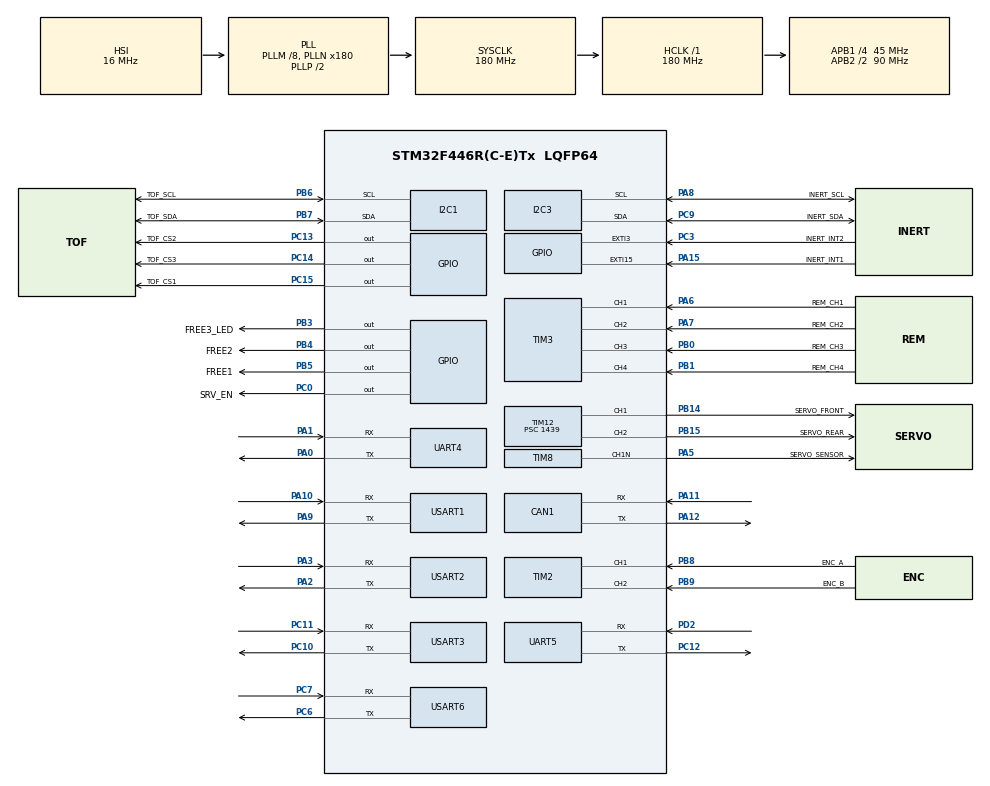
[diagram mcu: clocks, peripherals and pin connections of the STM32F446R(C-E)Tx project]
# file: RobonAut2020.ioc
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CAN1.CalculateTimeQuantum=355.55555555555554
FREERTOS.Tasks01=defaultTask,24,128,StartDefaultTask,Default,NULL,Dynamic,NULL,NULL
I2C1.I2C_Mode=I2C_Fast
Mcu.Family=STM32F4
Mcu.Name=STM32F446R(C-E)Tx
Mcu.Package=LQFP64
NVIC.I2C1_ER_IRQn=true\:5\:0\:false\:false\:true\:true\:true\:true
NVIC.I2C1_EV_IRQn=true\:5\:0\:false\:false\:true\:true\:true\:true
NVIC.I2C3_ER_IRQn=true\:5\:0\:false\:false\:true\:true\:true\:true
NVIC.I2C3_EV_IRQn=true\:5\:0\:false\:false\:true\:true\:true\:true
NVIC.PriorityGroup=NVIC_PRIORITYGROUP_4
NVIC.TIM2_IRQn=true\:5\:0\:false\:false\:true\:true\:true\:true
NVIC.TIM3_IRQn=true\:5\:0\:false\:false\:true\:true\:true\:true
NVIC.TIM7_IRQn=true\:0\:0\:false\:false\:true\:false\:false\:true
NVIC.TIM8_BRK_TIM12_IRQn=true\:5\:0\:false\:false\:true\:true\:true\:true
NVIC.TIM8_CC_IRQn=true\:5\:0\:false\:false\:true\:true\:true\:true
NVIC.TimeBase=TIM7_IRQn
NVIC.TimeBaseIP=TIM7
PA0-WKUP.Mode=Asynchronous
PA0-WKUP.Signal=UART4_TX
PA1.Mode=Asynchronous
PA1.Signal=UART4_RX
PA10.Mode=Asynchronous
PA10.Signal=USART1_RX
PA11.Mode=Master
PA11.Signal=CAN1_RX
PA12.Mode=Master
PA12.Signal=CAN1_TX
PA13.Mode=Serial_Wire
PA13.Signal=SYS_JTMS-SWDIO
PA14.Mode=Serial_Wire
PA14.Signal=SYS_JTCK-SWCLK
PA15.GPIO_Label=INERT_INT1
PA15.Signal=GPXTI15
PA2.Mode=Asynchronous
PA2.Signal=USART2_TX
PA3.Mode=Asynchronous
PA3.Signal=USART2_RX
PA5.GPIO_Label=SERVO_SENSOR
PA5.Mode=PWM Generation1 CH1N
PA5.Signal=TIM8_CH1N
PA6.GPIO_Label=REM_CH1
PA6.Signal=S_TIM3_CH1
PA7.GPIO_Label=REM_CH2
PA7.Signal=S_TIM3_CH2
PA8.GPIO_Label=INERT_SCL
PA8.Mode=I2C
PA8.Signal=I2C3_SCL
PA9.Mode=Asynchronous
PA9.Signal=USART1_TX
PB0.GPIO_Label=REM_CH3
PB0.Signal=S_TIM3_CH3
PB1.GPIO_Label=REM_CH4
PB1.Signal=S_TIM3_CH4
PB14.GPIO_Label=SERVO_FRONT
PB14.Signal=S_TIM12_CH1
PB15.GPIO_Label=SERVO_REAR
PB15.Signal=S_TIM12_CH2
PB3.GPIO_Label=FREE3_LED
PB3.Signal=GPIO_Output
PB4.GPIO_Label=FREE2
PB4.Signal=GPIO_Output
PB5.GPIO_Label=FREE1
PB5.Signal=GPIO_Output
PB6.GPIO_Label=TOF_SCL
PB6.Mode=I2C
PB6.Signal=I2C1_SCL
PB7.GPIO_Label=TOF_SDA
PB7.Mode=I2C
PB7.Signal=I2C1_SDA
PB8.GPIO_Label=ENC_A
PB8.Signal=S_TIM2_CH1_ETR
PB9.GPIO_Label=ENC_B
PB9.Signal=S_TIM2_CH2
PC0.GPIO_Label=SRV_EN
PC0.Signal=GPIO_Output
PC10.Mode=Asynchronous
PC10.Signal=USART3_TX
PC11.Mode=Asynchronous
PC11.Signal=USART3_RX
PC12.Mode=Asynchronous
PC12.Signal=UART5_TX
PC13.GPIO_Label=TOF_CS2
PC13.Signal=GPIO_Output
PC14-OSC32_IN.GPIO_Label=TOF_CS3
PC14-OSC32_IN.Signal=GPIO_Output
PC15-OSC32_OUT.GPIO_Label=TOF_CS1
PC15-OSC32_OUT.Signal=GPIO_Output
PC3.GPIO_Label=INERT_INT2
PC3.Signal=GPXTI3
PC6.Mode=Asynchronous
PC6.Signal=USART6_TX
PC7.Mode=Asynchronous
PC7.Signal=USART6_RX
PC9.GPIO_Label=INERT_SDA
PC9.Mode=I2C
PC9.Signal=I2C3_SDA
PD2.Mode=Asynchronous
PD2.Signal=UART5_RX
PH0-OSC_IN.Mode=HSE-External-Oscillator
PH0-OSC_IN.Signal=RCC_OSC_IN
PH1-OSC_OUT.Mode=HSE-External-Oscillator
PH1-OSC_OUT.Signal=RCC_OSC_OUT
ProjectManager.HeapSize=0x200
ProjectManager.StackSize=0x400
ProjectManager.TargetToolchain=STM32CubeIDE
RCC.AHBFreq_Value=180000000
RCC.APB1CLKDivider=RCC_HCLK_DIV4
RCC.APB1Freq_Value=45000000
RCC.APB1TimFreq_Value=90000000
RCC.APB2CLKDivider=RCC_HCLK_DIV2
RCC.APB2Freq_Value=90000000
RCC.APB2TimFreq_Value=180000000
RCC.CortexFreq_Value=180000000
RCC.HCLKFreq_Value=180000000
RCC.PLLM=8
RCC.PLLN=180
RCC.SYSCLKFreq_VALUE=180000000
RCC.SYSCLKSource=RCC_SYSCLKSOURCE_PLLCLK
RCC.USBFreq_Value=180000000
RCC.VCOOutputFreq_Value=360000000
SH.S_TIM12_CH1.0=TIM12_CH1,PWM Generation1 CH1
SH.S_TIM12_CH2.0=TIM12_CH2,PWM Generation2 CH2
SH.S_TIM2_CH1_ETR.0=TIM2_CH1,Encoder_Interface
SH.S_TIM2_CH2.0=TIM2_CH2,Encoder_Interface
SH.S_TIM3_CH1.0=TIM3_CH1,Input_Capture1_from_TI1
SH.S_TIM3_CH2.0=TIM3_CH2,Input_Capture2_from_TI2
SH.S_TIM3_CH3.0=TIM3_CH3,Input_Capture3_from_TI3
SH.S_TIM3_CH4.0=TIM3_CH4,Input_Capture4_from_TI4
TIM12.Channel-PWM\ Generation1\ CH1=TIM_CHANNEL_1
TIM12.Channel-PWM\ Generation2\ CH2=TIM_CHANNEL_2
TIM12.Period=249
TIM12.Prescaler=1439
TIM3.Channel-Input_Capture1_from_TI1=TIM_CHANNEL_1
TIM3.Channel-Input_Capture2_from_TI2=TIM_CHANNEL_2
TIM3.Channel-Input_Capture3_from_TI3=TIM_CHANNEL_3
TIM3.Channel-Input_Capture4_from_TI4=TIM_CHANNEL_4
TIM8.Channel-PWM\ Generation1\ CH1N=TIM_CHANNEL_1
TIM8.Period=1249
TIM8.Prescaler=1439
UART4.VirtualMode=Asynchronous
UART5.VirtualMode=Asynchronous
USART1.VirtualMode=VM_ASYNC
USART2.VirtualMode=VM_ASYNC
USART3.VirtualMode=VM_ASYNC
USART6.VirtualMode=VM_ASYNC
VP_FREERTOS_VS_CMSIS_V2.Mode=CMSIS_V2
VP_SYS_VS_tim7.Mode=TIM7
VP_TIM12_VS_ClockSourceINT.Mode=Internal
VP_TIM3_VS_ClockSourceINT.Mode=Internal
VP_TIM8_VS_ClockSourceINT.Mode=Internal
board=custom

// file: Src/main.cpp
/* USER CODE BEGIN Header */
/**
  ******************************************************************************
  * @file           : main.c
  * @brief          : Main program body
  ******************************************************************************
  * @attention
  *
  * <h2><center>&copy; Copyright (c) 2019 STMicroelectronics.
  * All rights reserved.</center></h2>
  *
  * This software component is licensed by ST under Ultimate Liberty license
  * SLA0044, the "License"; You may not use this file except in compliance with
  * the License. You may obtain a copy of the License at:
  *                             www.st.com/SLA0044
  *
  ******************************************************************************
  */
/* USER CODE END Header */

#include "main.h"
#include "cmsis_os.h"
#include "can.h"
#include "i2c.h"
#include "tim.h"
#include "usart.h"
#include "gpio.h"

void SystemClock_Config(void);
void MX_FREERTOS_Init(void);

int main(void)
{

  /* MCU Configuration--------------------------------------------------------*/

  /* Reset of all peripherals, Initializes the Flash interface and the Systick. */
  HAL_Init();

  /* Configure the system clock */
  SystemClock_Config();

  /* Initialize all configured peripherals */
  MX_GPIO_Init();
  MX_I2C1_Init();
  MX_USART2_UART_Init();
  MX_CAN1_Init();
  MX_I2C3_Init();
  MX_TIM2_Init();
  MX_TIM3_Init();
  MX_TIM8_Init();
  MX_TIM12_Init();
  MX_UART4_Init();
  MX_UART5_Init();
  MX_USART1_UART_Init();
  MX_USART3_UART_Init();
  MX_USART6_UART_Init();
  /* USER CODE BEGIN 2 */

  //HAL_TIM_PWM_Start(&htim12, TIM_CHANNEL_1);
  //HAL_TIM_PWM_Start(&htim12, TIM_CHANNEL_2);
  HAL_TIMEx_PWMN_Start(&htim8,  TIM_CHANNEL_1);

  __HAL_TIM_SET_COMPARE(&htim12, TIM_CHANNEL_1, 100);
  /* USER CODE END 2 */

  /* Call init function for freertos objects (in freertos.c) */
  MX_FREERTOS_Init();

  /* Start scheduler */
  osKernelStart();

  /* We should never get here as control is now taken by the scheduler */

  /* Infinite loop */
  while (1)
  {

  }
}

void SystemClock_Config(void)
{
  RCC_OscInitTypeDef RCC_OscInitStruct = {0};
  RCC_ClkInitTypeDef RCC_ClkInitStruct = {0};

  /** Configure the main internal regulator output voltage
  */
  __HAL_RCC_PWR_CLK_ENABLE();
  __HAL_PWR_VOLTAGESCALING_CONFIG(PWR_REGULATOR_VOLTAGE_SCALE1);
  /** Initializes the CPU, AHB and APB busses clocks
  */
  RCC_OscInitStruct.OscillatorType = RCC_OSCILLATORTYPE_HSI;
  RCC_OscInitStruct.HSIState = RCC_HSI_ON;
  RCC_OscInitStruct.HSICalibrationValue = RCC_HSICALIBRATION_DEFAULT;
  RCC_OscInitStruct.PLL.PLLState = RCC_PLL_ON;
  RCC_OscInitStruct.PLL.PLLSource = RCC_PLLSOURCE_HSI;
  RCC_OscInitStruct.PLL.PLLM = 8;
  RCC_OscInitStruct.PLL.PLLN = 180;
  RCC_OscInitStruct.PLL.PLLP = RCC_PLLP_DIV2;
  RCC_OscInitStruct.PLL.PLLQ = 2;
  RCC_OscInitStruct.PLL.PLLR = 2;
  if (HAL_RCC_OscConfig(&RCC_OscInitStruct) != HAL_OK)
  {
    Error_Handler();
  }
  /** Activate the Over-Drive mode
  */
  if (HAL_PWREx_EnableOverDrive() != HAL_OK)
  {
    Error_Handler();
  }
  /** Initializes the CPU, AHB and APB busses clocks
  */
  RCC_ClkInitStruct.ClockType = RCC_CLOCKTYPE_HCLK|RCC_CLOCKTYPE_SYSCLK
                              |RCC_CLOCKTYPE_PCLK1|RCC_CLOCKTYPE_PCLK2;
  RCC_ClkInitStruct.SYSCLKSource = RCC_SYSCLKSOURCE_PLLCLK;
  RCC_ClkInitStruct.AHBCLKDivider = RCC_SYSCLK_DIV1;
  RCC_ClkInitStruct.APB1CLKDivider = RCC_HCLK_DIV4;
  RCC_ClkInitStruct.APB2CLKDivider = RCC_HCLK_DIV2;

  if (HAL_RCC_ClockConfig(&RCC_ClkInitStruct, FLASH_LATENCY_5) != HAL_OK)
  {
    Error_Handler();
  }
}

void HAL_TIM_PeriodElapsedCallback(TIM_HandleTypeDef *htim)
{
  if (htim->Instance == TIM7) {
    HAL_IncTick();
  }
}

void Error_Handler(void)
{
}

/************************ (C) COPYRIGHT STMicroelectronics *****END OF FILE****/
